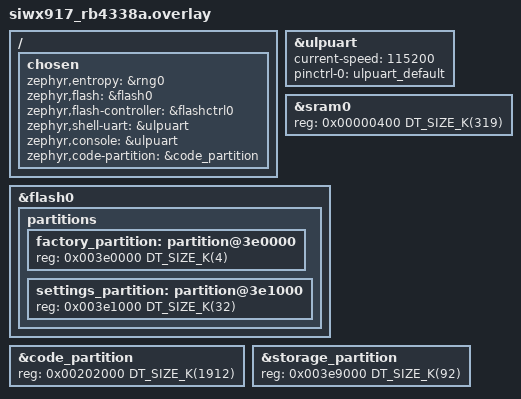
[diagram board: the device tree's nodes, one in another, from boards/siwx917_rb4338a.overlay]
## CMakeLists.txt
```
#
# Copyright (c) 2025 Project CHIP Authors
#
# Licensed under the Apache License, Version 2.0 (the "License");
# you may not use this file except in compliance with the License.
# You may obtain a copy of the License at
#
# http://www.apache.org/licenses/LICENSE-2.0
#
# Unless required by applicable law or agreed to in writing, software
# distributed under the License is distributed on an "AS IS" BASIS,
# WITHOUT WARRANTIES OR CONDITIONS OF ANY KIND, either express or implied.
# See the License for the specific language governing permissions and
# limitations under the License.
#
cmake_minimum_required(VERSION 3.20)

get_filename_component(CHIP_ROOT ${CMAKE_CURRENT_SOURCE_DIR}/../third_party/connectedhomeip REALPATH)
get_filename_component(GEN_DIR ${CHIP_ROOT}/zzz_generated/ REALPATH)
get_filename_component(ZEPHYR_PLATFORM_COMMON ${CHIP_ROOT}/examples/platform/silabs/zephyr REALPATH)
get_filename_component(SILABS_DISHWASHER_COMMON ${CHIP_ROOT}/examples/dishwasher-app/silabs REALPATH)


# Need this as wiseconnect abstraction is causing a build failure
add_definitions(-DMBEDTLS_X509_REMOVE_INFO )

list(APPEND ZEPHYR_EXTRA_MODULES ${CHIP_ROOT}/config/silabs)
find_package(Zephyr HINTS $ENV{ZEPHYR_BASE})

if(CONFIG_OPENTHREAD AND TARGET ot-config AND TARGET zephyr_interface)
    get_target_property(OT_CONFIG_DEFS ot-config INTERFACE_COMPILE_DEFINITIONS)
    if(OT_CONFIG_DEFS)
        list(FILTER OT_CONFIG_DEFS EXCLUDE REGEX "TARGET_PROPERTY:zephyr_interface,INTERFACE_COMPILE_DEFINITIONS")
    else()
        set(OT_CONFIG_DEFS "")
    endif()
    get_target_property(ZEPHYR_INTERFACE_DEFS zephyr_interface INTERFACE_COMPILE_DEFINITIONS)
    if(ZEPHYR_INTERFACE_DEFS)
        list(FILTER ZEPHYR_INTERFACE_DEFS EXCLUDE REGEX "COMPILE_LANGUAGE:CXX")
    else()
        set(ZEPHYR_INTERFACE_DEFS "")
    endif()
    set_target_properties(ot-config PROPERTIES
        INTERFACE_COMPILE_DEFINITIONS "${OT_CONFIG_DEFS};${ZEPHYR_INTERFACE_DEFS}")
endif()

if(CMAKE_C_COMPILER_ID STREQUAL "Clang")
    foreach(_mbedtls_lib mbedtls mbedx509 tfpsacrypto builtin p256-m pqcp extras platform utilities)
        if(TARGET ${_mbedtls_lib})
            target_compile_options(${_mbedtls_lib} PRIVATE -Wno-documentation -Wno-c99-extensions)
        endif()
    endforeach()

    if(CONFIG_OPENTHREAD)
        foreach(_ot_lib openthread-ftd openthread-mtd openthread-radio openthread-cli-ftd openthread-cli-mtd)
            if(TARGET ${_ot_lib})
                target_compile_options(${_ot_lib} PRIVATE -Wno-c99-extensions)
            endif()
        endforeach()
    endif()
endif()

# -Wmaybe-uninitialized has too many false positives, including on std::optional
# and chip::Optional.  Make it nonfatal.
#
# See https://gcc.gnu.org/bugzilla/show_bug.cgi?id=80635
target_compile_options(app PRIVATE -Werror -Wno-error=format)
if(CMAKE_C_COMPILER_ID STREQUAL "GNU")
    target_compile_options(app PRIVATE -Werror -Wno-error=maybe-uninitialized)
endif()

project(matter-zephyr-dishwasher)

include(${CHIP_ROOT}/config/silabs/app/enable-gnu-std.cmake)
include(${CHIP_ROOT}/src/app/chip_data_model.cmake)

target_include_directories(app
    PRIVATE
    include
    ${ZEPHYR_PLATFORM_COMMON}
)

target_sources(app
    PRIVATE
    src/AppTask.cpp
    src/DeviceCallbacks.cpp
    ../include/CHIPProjectConfig.h
    ${ZEPHYR_PLATFORM_COMMON}/main.cpp
    ${ZEPHYR_PLATFORM_COMMON}/AppTaskBase.cpp
    ${ZEPHYR_PLATFORM_COMMON}/AppTaskZephyr.cpp
    ${ZEPHYR_PLATFORM_COMMON}/CHIPDeviceManager.cpp
    ${ZEPHYR_PLATFORM_COMMON}/CommonDeviceCallbacks.cpp
    ${ZEPHYR_PLATFORM_COMMON}/DataModelCallbacks.cpp
)

if(CONFIG_CHIP_FACTORY_DATA)
    target_sources(app PRIVATE
                    ${CHIP_ROOT}/examples/platform/silabs/provision/ProvisionStorageZephyr.cpp
                    ${CHIP_ROOT}/examples/platform/silabs/provision/ProvisionStorageCommon.cpp
                    ${CHIP_ROOT}/examples/platform/silabs/provision/ProvisionStorageCustom.cpp
    )
    target_include_directories(app PRIVATE
                    ${CHIP_ROOT}/third_party/silabs/matter_support/provision
    )
    target_compile_definitions(app PRIVATE
        SL_PROVISION_GENERATOR=0
    )
endif()

if(CONFIG_CHIP_OTA_REQUESTOR)
    target_sources(app PRIVATE
                    ${ZEPHYR_PLATFORM_COMMON}/ota_requestor/source/OTARequestorInitiatorCommon.cpp
                    ${ZEPHYR_PLATFORM_COMMON}/ota_requestor/source/OTARequestorInitiatorZephyr.cpp
    )
    target_include_directories(app PRIVATE
                    ${ZEPHYR_PLATFORM_COMMON}/ota_requestor/include/
    )
endif()

if(CONFIG_CHIP_WIFI)
  chip_configure_data_model(app INCLUDE_SERVER
      ZAP_FILE ${SILABS_DISHWASHER_COMMON}/data_model/dishwasher-wifi-app.zap
  )
else()
  chip_configure_data_model(app INCLUDE_SERVER
      ZAP_FILE ${SILABS_DISHWASHER_COMMON}/data_model/dishwasher-thread-app.zap
  )
endif()

if(CONFIG_CHIP_LIB_SHELL)
    target_compile_definitions(app PRIVATE ENABLE_CHIP_SHELL)
    target_include_directories(app PRIVATE
                               ${CHIP_ROOT}/examples/shell/shell_common/include
                               ${ZEPHYR_PLATFORM_COMMON}/include
    )
    target_sources(app PRIVATE
                   ${ZEPHYR_PLATFORM_COMMON}/AppCLIZephyr.cpp
                   ${CHIP_ROOT}/examples/shell/shell_common/cmd_misc.cpp
                   ${CHIP_ROOT}/examples/shell/shell_common/cmd_otcli.cpp
                   ${CHIP_ROOT}/examples/shell/shell_common/cmd_server.cpp
    )
endif()

include(${CHIP_ROOT}/config/silabs/app/zephyr-post-build.cmake)
```

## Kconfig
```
#
#    Copyright (c) 2025 Project CHIP Authors
#
#    Licensed under the Apache License, Version 2.0 (the "License");
#    you may not use this file except in compliance with the License.
#    You may obtain a copy of the License at
#
#        http://www.apache.org/licenses/LICENSE-2.0
#
#    Unless required by applicable law or agreed to in writing, software
#    distributed under the License is distributed on an "AS IS" BASIS,
#    WITHOUT WARRANTIES OR CONDITIONS OF ANY KIND, either express or implied.
#    See the License for the specific language governing permissions and
#    limitations under the License.
#
mainmenu "Matter Silabs Dishwasher Example Application"

# Sample configuration used for Thread networking
if NET_L2_OPENTHREAD
choice OPENTHREAD_DEVICE_TYPE
	default OPENTHREAD_FTD
endchoice
endif # NET_L2_OPENTHREAD

rsource "../../../../config/silabs/Kconfig.defaults"
rsource "../../../../config/silabs/Kconfig"
source "Kconfig.zephyr"
```

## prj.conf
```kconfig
#
#    Copyright (c) 2025 Project CHIP Authors
#
#    Licensed under the Apache License, Version 2.0 (the "License");
#    you may not use this file except in compliance with the License.
#    You may obtain a copy of the License at
#
#        http://www.apache.org/licenses/LICENSE-2.0
#
#    Unless required by applicable law or agreed to in writing, software
#    distributed under the License is distributed on an "AS IS" BASIS,
#    WITHOUT WARRANTIES OR CONDITIONS OF ANY KIND, either express or implied.
#    See the License for the specific language governing permissions and
#    limitations under the License.
#

# This sample uses Kconfig.defaults to set options common for all
# samples. This file should contain only options specific for this sample
# or overrides of default values.

# Enable CHIP
CONFIG_CHIP=y
CONFIG_CHIP_PROJECT_CONFIG="../include/CHIPProjectConfig.h"
# 32773 == 0x8005 (example dishwasher-app)
CONFIG_CHIP_DEVICE_PRODUCT_ID=32773
CONFIG_STD_CPP17=y

CONFIG_GPIO=y

# Enable Matter extended announcement and increase duration to 1 hour.
CONFIG_CHIP_ENABLE_PAIRING_AUTOSTART=y
CONFIG_CHIP_BLE_EXT_ADVERTISING=y
CONFIG_CHIP_BLE_ADVERTISING_DURATION=60

CONFIG_LOG_MODE_MINIMAL=n
CONFIG_LOG_MODE_DEFERRED=y
CONFIG_LOG_BUFFER_SIZE=8192

CONFIG_SYSTEM_WORKQUEUE_STACK_SIZE=4096
CONFIG_MAIN_STACK_SIZE=8192
CONFIG_MBEDTLS_HEAP_SIZE=16384
CONFIG_SHELL_STACK_SIZE=4096
CONFIG_SHELL_THREAD_PRIORITY_OVERRIDE=y
CONFIG_SHELL_THREAD_PRIORITY=11
CONFIG_SHELL_BACKEND_SERIAL_LOG_MESSAGE_QUEUE_SIZE=2048

CONFIG_LOG_PROCESS_THREAD_CUSTOM_PRIORITY=y
CONFIG_LOG_PROCESS_THREAD_PRIORITY=12

CONFIG_UART_ASYNC_API=y

CONFIG_SECURE_STORAGE_ITS_TRANSFORM_AEAD_SCHEME_AES_GCM=y
CONFIG_CHIP_LIB_SHELL=y

CONFIG_BT_HOST_CRYPTO=y

CONFIG_NET_IF_MCAST_IPV6_ADDR_COUNT=5

CONFIG_BT_RECV_WORKQ_BT=n

# Bluetooth Low Energy configuration
CONFIG_BT_DEVICE_NAME="MatterDishwasher"

# Reduce application size
CONFIG_USE_SEGGER_RTT=n

# Avoid getopt multiple-definition conflict between newlib nano and Zephyr's POSIX C lib extension.
# Newlib already provides getopt, strnlen, gmtime_r, strtok_r, etc.
CONFIG_POSIX_AEP_CHOICE_NONE=y

# CHIP's libCHIP.a uses thread_local storage (e.g. ErrorStr.cpp) which requires __aeabi_read_tp
CONFIG_THREAD_LOCAL_STORAGE=y

CONFIG_SETTINGS_NVS_SECTOR_COUNT=6
```

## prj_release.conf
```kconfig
#
#    Copyright (c) 2025 Project CHIP Authors
#
#    Licensed under the Apache License, Version 2.0 (the "License");
#    you may not use this file except in compliance with the License.
#    You may obtain a copy of the License at
#
#        http://www.apache.org/licenses/LICENSE-2.0
#
#    Unless required by applicable law or agreed to in writing, software
#    distributed under the License is distributed on an "AS IS" BASIS,
#    WITHOUT WARRANTIES OR CONDITIONS OF ANY KIND, either express or implied.
#    See the License for the specific language governing permissions and
#    limitations under the License.
#

# This sample uses Kconfig.defaults to set options common for all
# samples. This file should contain only options specific for this sample
# or overrides of default values.

# Enable CHIP
CONFIG_CHIP=y
CONFIG_CHIP_PROJECT_CONFIG="../include/CHIPProjectConfig.h"
# 32773 == 0x8005 (example dishwasher-app)
CONFIG_CHIP_DEVICE_PRODUCT_ID=32773
CONFIG_STD_CPP17=y

# Enable Matter pairing automatically on application start.
CONFIG_CHIP_ENABLE_PAIRING_AUTOSTART=y

# Enable Matter extended announcement and increase duration to 1 hour.
CONFIG_CHIP_BLE_EXT_ADVERTISING=y
CONFIG_CHIP_BLE_ADVERTISING_DURATION=60

# General networking settings
CONFIG_NET_IF_MCAST_IPV6_ADDR_COUNT=14

# Bluetooth Low Energy configuration
CONFIG_BT_DEVICE_NAME="MatterDishwasher"

# Disable all debug features
CONFIG_USE_SEGGER_RTT=n
CONFIG_SHELL=n
CONFIG_OPENTHREAD_SHELL=n
CONFIG_CONSOLE=n
CONFIG_UART_CONSOLE=n
CONFIG_SERIAL=n
CONFIG_LOG=n
CONFIG_LOG_MODE_MINIMAL=n
CONFIG_ASSERT_VERBOSE=n
CONFIG_ASSERT_NO_FILE_INFO=y
CONFIG_PRINTK=n
CONFIG_PRINTK_SYNC=n
CONFIG_BOOT_BANNER=n
```

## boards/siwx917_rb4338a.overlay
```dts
/*
 *    Copyright (c) 2025 Project CHIP Authors
 *    All rights reserved.
 *
 *    Licensed under the Apache License, Version 2.0 (the "License");
 *    you may not use this file except in compliance with the License.
 *    You may obtain a copy of the License at
 *
 *        http://www.apache.org/licenses/LICENSE-2.0
 *
 *    Unless required by applicable law or agreed to in writing, software
 *    distributed under the License is distributed on an "AS IS" BASIS
 *    WITHOUT WARRANTIES OR CONDITIONS OF ANY KIND, either express or implied.
 *    See the License for the specific language governing permissions and
 *    limitations under the License.
 */

/ {
	chosen {
		zephyr,entropy = &rng0;
		zephyr,flash = &flash0;
		zephyr,flash-controller = &flashctrl0;
		zephyr,shell-uart = &ulpuart;
		zephyr,console = &ulpuart;
		zephyr,code-partition = &code_partition;
	};
};

&ulpuart {
	status = "okay";
	current-speed = <115200>;
	pinctrl-0 = <&ulpuart_default>;
	pinctrl-names = "default";
};

&sram0 {
	status = "okay";
	reg = <0x00000400 DT_SIZE_K(319)>;
};

&flash0 {
	partitions {
		factory_partition: partition@3e0000 {
			reg = <0x003e0000 DT_SIZE_K(4)>;
		};

		settings_partition: partition@3e1000 {
			reg = <0x003e1000 DT_SIZE_K(32)>;
		};
	};
};

&code_partition {
	reg = <0x00202000 DT_SIZE_K(1912)>;
};

&storage_partition {
	reg = <0x003e9000 DT_SIZE_K(92)>;
};
```

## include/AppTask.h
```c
/*
 *
 *    Copyright (c) 2025 Project CHIP Authors
 *    All rights reserved.
 *
 *    Licensed under the Apache License, Version 2.0 (the "License");
 *    you may not use this file except in compliance with the License.
 *    You may obtain a copy of the License at
 *
 *        http://www.apache.org/licenses/LICENSE-2.0
 *
 *    Unless required by applicable law or agreed to in writing, software
 *    distributed under the License is distributed on an "AS IS" BASIS,
 *    WITHOUT WARRANTIES OR CONDITIONS OF ANY KIND, either express or implied.
 *    See the License for the specific language governing permissions and
 *    limitations under the License.
 */

#pragma once

#include "AppTaskZephyr.h"

#include <app/clusters/operational-state-server/operational-state-server.h>
#include <lib/core/ClusterEnums.h>

class AppTask : public chip::Zephyr::App::AppTaskZephyr
{
public:
    using OperationalStateEnum = chip::app::Clusters::OperationalState::OperationalStateEnum;

    ~AppTask() override{};
    void PreInitMatterStack(void) override;
    void PostInitMatterStack(void) override;
    void PostInitMatterServerInstance(void) override;

    static AppTask & GetDefaultInstance();

    static void ActionInitiated(OperationalStateEnum action);
    static void ActionCompleted();

private:
};

chip::Zephyr::App::AppTaskBase & GetAppTask();

/**
 * Drive LED1 from dishwasher operational state (on=Running, blink patterns for Pause/Error).
 * No-op if LED1 is not available on the board.
 */
void UpdateOperationalStateLed(chip::app::Clusters::OperationalState::OperationalStateEnum state);

/**
 * Apply fake EPM readings for the given operational state (endpoint 2 electrical sensor).
 */
void UpdateEpmAttributesForOperationalState(chip::app::Clusters::OperationalState::OperationalStateEnum state);
```

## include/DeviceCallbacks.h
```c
/*
 *
 *    Copyright (c) 2026 Project CHIP Authors
 *    All rights reserved.
 *
 *    Licensed under the Apache License, Version 2.0 (the "License");
 *    you may not use this file except in compliance with the License.
 *    You may obtain a copy of the License at
 *
 *        http://www.apache.org/licenses/LICENSE-2.0
 *
 *    Unless required by applicable law or agreed to in writing, software
 *    distributed under the License is distributed on an "AS IS" BASIS,
 *    WITHOUT WARRANTIES OR CONDITIONS OF ANY KIND, either express or implied.
 *    See the License for the specific language governing permissions and
 *    limitations under the License.
 */

/**
 * @file DeviceCallbacks.h
 *
 * Dishwasher app DeviceManager callbacks (skeleton).
 *
 **/

#pragma once

#include "CHIPDeviceManager.h"
#include "CommonDeviceCallbacks.h"

namespace DishwasherApp {

class DeviceCallbacks : public chip::Zephyr::App::CommonDeviceCallbacks
{
public:
    void PostAttributeChangeCallback(chip::EndpointId endpoint, chip::ClusterId clusterId, chip::AttributeId attributeId,
                                     uint8_t type, uint16_t size, uint8_t * value) override;
};

} // namespace DishwasherApp

namespace chip::Zephyr::App {

chip::DeviceManager::CHIPDeviceManagerCallbacks & GetDeviceCallbacks();

} // namespace chip::Zephyr::App
```

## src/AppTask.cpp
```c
/*
 *
 *    Copyright (c) 2025 Project CHIP Authors
 *    All rights reserved.
 *
 *    Licensed under the Apache License, Version 2.0 (the "License");
 *    you may not use this file except in compliance with the License.
 *    You may obtain a copy of the License at
 *
 *        http://www.apache.org/licenses/LICENSE-2.0
 *
 *    Unless required by applicable law or agreed to in writing, software
 *    distributed under the License is distributed on an "AS IS" BASIS,
 *    WITHOUT WARRANTIES OR CONDITIONS OF ANY KIND, either express or implied.
 *    See the License for the specific language governing permissions and
 *    limitations under the License.
 */

#include "AppTask.h"
#include "CHIPDeviceManager.h"

#include "DataModelHelper.h"
#include "DeviceEnergyManager.h"
#include "DishwasherManager.h"
#include "operational-state-delegate-impl.h"

#include <DEMConfig.h>
#include <ElectricalSensorManager.h>

#include <app-common/zap-generated/ids/Attributes.h>
#include <app-common/zap-generated/ids/Clusters.h>
#include <app/server/Server.h>
#include <app/util/attribute-storage.h>
#include <lib/support/CodeUtils.h>
#include <platform/CHIPDeviceLayer.h>

#include <memory>

#include <zephyr/drivers/gpio.h>
#include <zephyr/kernel.h>
#include <zephyr/logging/log.h>

LOG_MODULE_DECLARE(app, CONFIG_CHIP_APP_LOG_LEVEL);

using namespace chip;
using namespace chip::DeviceLayer;
using namespace chip::app;
using namespace chip::app::Clusters;
using namespace chip::app::Clusters::DeviceEnergyManagement;
using namespace chip::app::Clusters::ElectricalEnergyMeasurement;
using namespace chip::app::Clusters::ElectricalPowerMeasurement;
using namespace chip::app::Clusters::OperationalState;
using namespace chip::app::Clusters::PowerTopology;
using namespace chip::app::DataModel;

namespace {

/* -------------------------------------------------------------------------- */
/*                          LED / button DT bindings                          */
/* -------------------------------------------------------------------------- */

#if DT_NODE_EXISTS(DT_ALIAS(led0))
#define HAS_LED0 1
static const struct gpio_dt_spec sLed0 = GPIO_DT_SPEC_GET(DT_ALIAS(led0), gpios);
static struct k_timer sLed0BlinkTimer;
static bool sLed0State;
#endif

#if DT_NODE_EXISTS(DT_ALIAS(led1))
#define HAS_LED1 1
static const struct gpio_dt_spec sLed1 = GPIO_DT_SPEC_GET(DT_ALIAS(led1), gpios);
static struct k_timer sLed1BlinkTimer;
static bool sLed1State;
static bool sLed1BlinkActive;
#endif

#if DT_NODE_EXISTS(DT_ALIAS(sw0))
#define HAS_BUTTON0 1
static const struct gpio_dt_spec sButton0 = GPIO_DT_SPEC_GET(DT_ALIAS(sw0), gpios);
static struct gpio_callback sButton0CbData;
static struct k_work_delayable sFactoryResetWarningWork;
static struct k_work_delayable sFactoryResetTriggerWork;
#endif

#if DT_NODE_EXISTS(DT_ALIAS(sw1))
#define HAS_BUTTON1 1
static const struct gpio_dt_spec sButton1 = GPIO_DT_SPEC_GET(DT_ALIAS(sw1), gpios);
static struct gpio_callback sButton1CbData;
static struct k_work sCycleOpStateWork;
#endif

/* -------------------------------------------------------------------------- */
/*                     Electrical sensor (endpoint 2)                         */
/* -------------------------------------------------------------------------- */

const ElectricalEnergyMeasurement::Structs::MeasurementAccuracyRangeStruct::Type kMeasurementAccuracyRanges[] = {
    { .rangeMin   = 0,
      .rangeMax   = 1'000'000'000'000'000,
      .percentMax = MakeOptional(static_cast<chip::Percent100ths>(500)),
      .percentMin = MakeOptional(static_cast<chip::Percent100ths>(50)) }
};

const ElectricalEnergyMeasurement::Structs::MeasurementAccuracyStruct::Type kMeasurementAccuracy = {
    .measurementType  = MeasurementTypeEnum::kElectricalEnergy,
    .measured         = true,
    .minMeasuredValue = 0,
    .maxMeasuredValue = 1'000'000'000'000'000,
    .accuracyRanges   = DataModel::List<const ElectricalEnergyMeasurement::Structs::MeasurementAccuracyRangeStruct::Type>(
        kMeasurementAccuracyRanges)
};

std::unique_ptr<ElectricalSensorManager> gESManager;

// EPM attribute values indexed by OperationalStateEnum (Stopped/Running/Paused/Error)
static const struct
{
    int64_t Voltage;       // mV
    int64_t ActiveCurrent; // mA
    int64_t ActivePower;   // mW
} kAttributes[4] = {
    { 120'000, 0, 0 },             // kStopped
    { 120'000, 15'000, 1800'000 }, // kRunning
    { 120'000, 125, 17'000 },      // kPaused
    { 0, 0, 0 },                   // kError
};

#ifdef HAS_LED0
static void Led0BlinkTimerHandler(struct k_timer * timer)
{
    sLed0State = !sLed0State;
    gpio_pin_set_dt(&sLed0, static_cast<int>(sLed0State));
}
#endif

#ifdef HAS_LED1
static void Led1BlinkTimerHandler(struct k_timer * timer)
{
    sLed1State = !sLed1State;
    gpio_pin_set_dt(&sLed1, static_cast<int>(sLed1State));
}

static void StopLed1Blink()
{
    if (sLed1BlinkActive)
    {
        k_timer_stop(&sLed1BlinkTimer);
        sLed1BlinkActive = false;
    }
}
#endif

#ifdef HAS_BUTTON0
static void FactoryResetWarningWorkHandler(struct k_work * work)
{
    LOG_INF("Keep holding to factory reset in 3 seconds. Release to cancel.");
}

static void FactoryResetTriggerWorkHandler(struct k_work * work)
{
    LOG_INF("Factory reset triggered");
    chip::Server::GetInstance().ScheduleFactoryReset();
}

static void Button0PressedHandler(const struct device * dev, struct gpio_callback * cb, uint32_t pins)
{
    if (gpio_pin_get_dt(&sButton0) > 0)
    {
        k_work_schedule(&sFactoryResetWarningWork, K_SECONDS(2));
        k_work_schedule(&sFactoryResetTriggerWork, K_SECONDS(5));
    }
    else
    {
        bool wasPending = k_work_cancel_delayable(&sFactoryResetTriggerWork) != 0;
        k_work_cancel_delayable(&sFactoryResetWarningWork);
        if (wasPending)
        {
            LOG_INF("Factory reset canceled");
        }
    }
}
#endif

#ifdef HAS_BUTTON1
static void CycleOperationalStateWork(intptr_t arg)
{
    static_cast<void>(arg);
    DishwasherManager * mgr = GetDishwasherManager();
    if (mgr != nullptr)
    {
        mgr->CycleOperationalState();
    }
}

static void CycleOpStateWorkHandler(struct k_work * work)
{
    static_cast<void>(work);
    RETURN_SAFELY_IGNORED PlatformMgr().ScheduleWork(CycleOperationalStateWork, 0);
}

static void Button1PressedHandler(const struct device * dev, struct gpio_callback * cb, uint32_t pins)
{
    k_work_submit(&sCycleOpStateWork);
}
#endif

CHIP_ERROR InitElectricalSensorManager()
{
    EndpointId endpointId = DataModelHelper::GetEndpointIdFromCluster(ElectricalPowerMeasurement::Id);
    VerifyOrReturnError(endpointId != kInvalidEndpointId, CHIP_ERROR_INCORRECT_STATE,
                        ChipLogError(AppServer, "EPM cluster endpoint not found"));

    VerifyOrReturnError(!gESManager, CHIP_ERROR_INCORRECT_STATE, ChipLogError(AppServer, "ES manager already initialized"));

    gESManager = std::make_unique<ElectricalSensorManager>();
    VerifyOrReturnError(gESManager, CHIP_ERROR_NO_MEMORY);

    ElectricalSensorManager::EpmConfig epmConfig{
        .features = BitMask<ElectricalPowerMeasurement::Feature, uint32_t>(
            ElectricalPowerMeasurement::Feature::kDirectCurrent, ElectricalPowerMeasurement::Feature::kAlternatingCurrent),
        .optionalAttributes = BitMask<ElectricalPowerMeasurement::OptionalAttributes, uint32_t>(
            ElectricalPowerMeasurement::OptionalAttributes::kOptionalAttributeVoltage,
            ElectricalPowerMeasurement::OptionalAttributes::kOptionalAttributeActiveCurrent),
    };

    ElectricalSensorManager::EemConfig eemConfig{
        .features = BitMask<ElectricalEnergyMeasurement::Feature, uint32_t>(
            ElectricalEnergyMeasurement::Feature::kImportedEnergy, ElectricalEnergyMeasurement::Feature::kCumulativeEnergy),
        .optionalAttributes = ElectricalEnergyMeasurement::ElectricalEnergyMeasurementCluster::OptionalAttributesSet()
                                  .Set<ElectricalEnergyMeasurement::Attributes::CumulativeEnergyReset::Id>(),
        .accuracyStruct = kMeasurementAccuracy,
    };

    ElectricalSensorManager::PtConfig ptConfig{
        .features = BitMask<PowerTopology::Feature, uint32_t>(PowerTopology::Feature::kNodeTopology),
    };

    ReturnErrorOnFailure(gESManager->Init(endpointId, epmConfig, eemConfig, ptConfig));
    return CHIP_NO_ERROR;
}

} // namespace

ElectricalSensorManager * GetESManager()
{
    return gESManager.get();
}

void UpdateEpmAttributesForOperationalState(OperationalStateEnum state)
{
    VerifyOrReturn(gESManager != nullptr);

    size_t index = 0;
    switch (state)
    {
    case OperationalStateEnum::kStopped:
        index = 0;
        break;
    case OperationalStateEnum::kRunning:
        index = 1;
        break;
    case OperationalStateEnum::kPaused:
        index = 2;
        break;
    case OperationalStateEnum::kError:
    default:
        index = 3;
        break;
    }

    chip::ChipError err =
        gESManager->SendPowerReading(kAttributes[index].ActivePower, kAttributes[index].Voltage, kAttributes[index].ActiveCurrent);
    VerifyOrReturn(err == CHIP_NO_ERROR,
                   ChipLogError(AppServer, "ERR: updating EPM attributes for operational state %" CHIP_ERROR_FORMAT, err.Format()));
}

void UpdateOperationalStateLed(OperationalStateEnum state)
{
#ifdef HAS_LED1
    VerifyOrReturn(gpio_is_ready_dt(&sLed1));

    StopLed1Blink();
    sLed1State = false;
    gpio_pin_set_dt(&sLed1, 0);

    switch (state)
    {
    case OperationalStateEnum::kRunning:
        gpio_pin_set_dt(&sLed1, 1);
        sLed1State = true;
        break;
    case OperationalStateEnum::kPaused:
        sLed1BlinkActive = true;
        // ~300 ms on / 700 ms off
        k_timer_start(&sLed1BlinkTimer, K_MSEC(300), K_MSEC(1000));
        break;
    case OperationalStateEnum::kError:
        sLed1BlinkActive = true;
        k_timer_start(&sLed1BlinkTimer, K_MSEC(100), K_MSEC(100));
        break;
    case OperationalStateEnum::kStopped:
    default:
        break;
    }
#else
    (void) state;
#endif
}

void AppTask::ActionInitiated(OperationalStateEnum action)
{
    if (action == OperationalStateEnum::kRunning)
    {
        ChipLogProgress(DeviceLayer, "Starting dishwasher");
    }
    else if (action == OperationalStateEnum::kStopped)
    {
        ChipLogProgress(DeviceLayer, "Stopping dishwasher");
    }
    else if (action == OperationalStateEnum::kPaused)
    {
        ChipLogProgress(DeviceLayer, "Pausing dishwasher");
    }
    else
    {
        ChipLogProgress(DeviceLayer, "Dishwasher action error");
        action = OperationalStateEnum::kError;
    }

    PlatformMgr().LockChipStack();
    CHIP_ERROR err = OperationalState::GetInstance()->SetOperationalState(to_underlying(action));
    PlatformMgr().UnlockChipStack();

    VerifyOrReturn(err == CHIP_NO_ERROR,
                   ChipLogError(DeviceLayer, "ERR: updating Operational state %" CHIP_ERROR_FORMAT, err.Format()));

    GetDishwasherManager()->UpdateOperationState(action);
    UpdateEpmAttributesForOperationalState(action);
}

void AppTask::ActionCompleted()
{
    // LED already updated in UpdateOperationState -> UpdateDishwasherLed.
}

void AppTask::PreInitMatterStack()
{
    ChipLogProgress(DeviceLayer, "Welcome to Zephyr Matter Dishwasher Demo App");

#ifdef HAS_LED0
    if (gpio_is_ready_dt(&sLed0))
    {
        VerifyOrDie(gpio_pin_configure_dt(&sLed0, GPIO_OUTPUT_INACTIVE) == 0);
        k_timer_init(&sLed0BlinkTimer, Led0BlinkTimerHandler, nullptr);
    }
#endif

#ifdef HAS_LED1
    if (gpio_is_ready_dt(&sLed1))
    {
        VerifyOrDie(gpio_pin_configure_dt(&sLed1, GPIO_OUTPUT_INACTIVE) == 0);
        k_timer_init(&sLed1BlinkTimer, Led1BlinkTimerHandler, nullptr);
    }
#endif

#ifdef HAS_BUTTON0
    k_work_init_delayable(&sFactoryResetWarningWork, FactoryResetWarningWorkHandler);
    k_work_init_delayable(&sFactoryResetTriggerWork, FactoryResetTriggerWorkHandler);

    if (gpio_is_ready_dt(&sButton0))
    {
        VerifyOrDie(gpio_pin_configure_dt(&sButton0, GPIO_INPUT) == 0);
        VerifyOrDie(gpio_pin_interrupt_configure_dt(&sButton0, GPIO_INT_EDGE_BOTH) == 0);
        gpio_init_callback(&sButton0CbData, Button0PressedHandler, BIT(sButton0.pin));
        gpio_add_callback(sButton0.port, &sButton0CbData);
    }
#endif

#ifdef HAS_BUTTON1
    k_work_init(&sCycleOpStateWork, CycleOpStateWorkHandler);

    if (gpio_is_ready_dt(&sButton1))
    {
        VerifyOrDie(gpio_pin_configure_dt(&sButton1, GPIO_INPUT) == 0);
        VerifyOrDie(gpio_pin_interrupt_configure_dt(&sButton1, GPIO_INT_EDGE_TO_ACTIVE) == 0);
        gpio_init_callback(&sButton1CbData, Button1PressedHandler, BIT(sButton1.pin));
        gpio_add_callback(sButton1.port, &sButton1CbData);
    }
#endif
}

void AppTask::PostInitMatterStack()
{
#ifdef HAS_LED0
    if (ConnectivityMgr().IsBLEAdvertisingEnabled())
    {
        sLed0State = false;
        k_timer_start(&sLed0BlinkTimer, K_MSEC(500), K_MSEC(500));
    }
#endif
}

void AppTask::PostInitMatterServerInstance()
{
    CHIP_ERROR err = DeviceEnergyManager::Instance().Init();
    VerifyOrReturn(err == CHIP_NO_ERROR,
                   ChipLogError(DeviceLayer, "DeviceEnergyManager.Init failed: %" CHIP_ERROR_FORMAT, err.Format()));

    err = InitElectricalSensorManager();
    VerifyOrReturn(err == CHIP_NO_ERROR,
                   ChipLogError(DeviceLayer, "ElectricalSensorManager.Init failed: %" CHIP_ERROR_FORMAT, err.Format()));

    GetDishwasherManager()->SetCallbacks(ActionInitiated, ActionCompleted);

    OperationalStateEnum state = static_cast<OperationalStateEnum>(OperationalState::GetInstance()->GetCurrentOperationalState());
    GetDishwasherManager()->UpdateOperationState(state);
    UpdateEpmAttributesForOperationalState(state);
}

AppTask & AppTask::GetDefaultInstance()
{
    static AppTask sAppTask;
    return sAppTask;
}

chip::Zephyr::App::AppTaskBase & chip::Zephyr::App::GetAppTask()
{
    return AppTask::GetDefaultInstance();
}
```

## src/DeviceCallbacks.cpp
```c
/*
 *
 *    Copyright (c) 2026 Project CHIP Authors
 *    All rights reserved.
 *
 *    Licensed under the Apache License, Version 2.0 (the "License");
 *    you may not use this file except in compliance with the License.
 *    You may obtain a copy of the License at
 *
 *        http://www.apache.org/licenses/LICENSE-2.0
 *
 *    Unless required by applicable law or agreed to in writing, software
 *    distributed under the License is distributed on an "AS IS" BASIS,
 *    WITHOUT WARRANTIES OR CONDITIONS OF ANY KIND, either express or implied.
 *    See the License for the specific language governing permissions and
 *    limitations under the License.
 */

#include <lib/support/logging/CHIPLogging.h>

#include "AppTask.h"
#include "DeviceCallbacks.h"
#include "DishwasherManager.h"

#include <app-common/zap-generated/ids/Attributes.h>
#include <app-common/zap-generated/ids/Clusters.h>

using namespace ::chip;
using namespace ::chip::app::Clusters;
using namespace ::chip::app::Clusters::DeviceEnergyManagement;
using namespace ::chip::app::Clusters::OperationalState;

void DishwasherApp::DeviceCallbacks::PostAttributeChangeCallback(chip::EndpointId endpoint, chip::ClusterId clusterId,
                                                                 chip::AttributeId attributeId, uint8_t type, uint16_t size,
                                                                 uint8_t * value)
{
    if ((clusterId == OperationalState::Id) && (attributeId == OperationalState::Attributes::OperationalState::Id))
    {
        VerifyOrReturn(value != nullptr);
        OperationalState::OperationalStateEnum state = static_cast<OperationalState::OperationalStateEnum>(*value);
        DishwasherManager * mgr                      = GetDishwasherManager();
        if (mgr != nullptr)
        {
            mgr->UpdateOperationState(state);
        }
        UpdateEpmAttributesForOperationalState(state);
    }
    else if (clusterId == Identify::Id)
    {
        ChipLogProgress(Zcl, "Identify attribute ID: " ChipLogFormatMEI " Type: %u Value: %u, length %u",
                        ChipLogValueMEI(attributeId), type, *value, size);
    }
}

chip::DeviceManager::CHIPDeviceManagerCallbacks & chip::Zephyr::App::GetDeviceCallbacks()
{
    static DishwasherApp::DeviceCallbacks sDeviceCallbacks;
    return sDeviceCallbacks;
}
```
